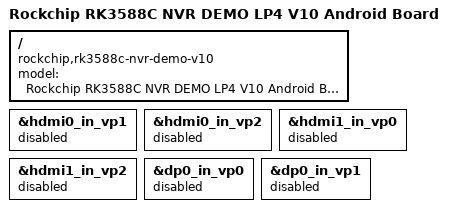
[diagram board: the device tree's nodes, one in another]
// SPDX-License-Identifier: (GPL-2.0+ OR MIT)
/*
 * Copyright (c) 2022 Rockchip Electronics Co., Ltd.
 *
 */

/dts-v1/;

#include "rk3588c-nvr-demo.dtsi"
#include "rk3588-android.dtsi"

/ {
	model = "Rockchip RK3588C NVR DEMO LP4 V10 Android Board";
	compatible = "rockchip,rk3588c-nvr-demo-v10", "rockchip,rk3588";
};

&hdmi0_in_vp1 {
	status = "disabled";
};

&hdmi0_in_vp2 {
	status = "disabled";
};

&hdmi1_in_vp0 {
	status = "disabled";
};

&hdmi1_in_vp2 {
	status = "disabled";
};

&dp0_in_vp0 {
	status = "disabled";
};

&dp0_in_vp1 {
	status = "disabled";
};
